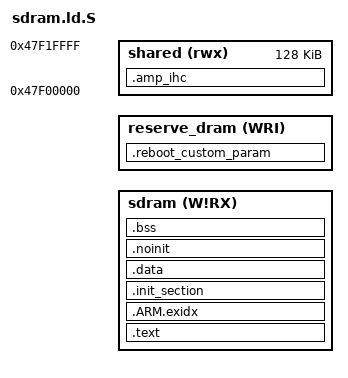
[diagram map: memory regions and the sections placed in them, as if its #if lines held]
/* Copyright (c) 2019-2025 Allwinner Technology Co., Ltd. ALL rights reserved.

 * Allwinner is a trademark of Allwinner Technology Co.,Ltd., registered in
 * the the People's Republic of China and other countries.
 * All Allwinner Technology Co.,Ltd. trademarks are used with permission.

 * DISCLAIMER
 * THIRD PARTY LICENCES MAY BE REQUIRED TO IMPLEMENT THE SOLUTION/PRODUCT.
 * IF YOU NEED TO INTEGRATE THIRD PARTY’S TECHNOLOGY (SONY, DTS, DOLBY, AVS OR MPEGLA, ETC.)
 * IN ALLWINNERS’SDK OR PRODUCTS, YOU SHALL BE SOLELY RESPONSIBLE TO OBTAIN
 * ALL APPROPRIATELY REQUIRED THIRD PARTY LICENCES.
 * ALLWINNER SHALL HAVE NO WARRANTY, INDEMNITY OR OTHER OBLIGATIONS WITH RESPECT TO MATTERS
 * COVERED UNDER ANY REQUIRED THIRD PARTY LICENSE.
 * YOU ARE SOLELY RESPONSIBLE FOR YOUR USAGE OF THIRD PARTY’S TECHNOLOGY.


 * THIS SOFTWARE IS PROVIDED BY ALLWINNER"AS IS" AND TO THE MAXIMUM EXTENT
 * PERMITTED BY LAW, ALLWINNER EXPRESSLY DISCLAIMS ALL WARRANTIES OF ANY KIND,
 * WHETHER EXPRESS, IMPLIED OR STATUTORY, INCLUDING WITHOUT LIMITATION REGARDING
 * THE TITLE, NON-INFRINGEMENT, ACCURACY, CONDITION, COMPLETENESS, PERFORMANCE
 * OR MERCHANTABILITY AND FITNESS FOR A PARTICULAR PURPOSE.
 * IN NO EVENT SHALL ALLWINNER BE LIABLE FOR ANY DIRECT, INDIRECT, INCIDENTAL,
 * SPECIAL, EXEMPLARY, OR CONSEQUENTIAL DAMAGES (INCLUDING, BUT
 * NOT LIMITED TO, PROCUREMENT OF SUBSTITUTE GOODS OR SERVICES;
 * LOSS OF USE, DATA, OR PROFITS, OR BUSINESS INTERRUPTION)
 * HOWEVER CAUSED AND ON ANY THEORY OF LIABILITY, WHETHER IN CONTRACT,
 * STRICT LIABILITY, OR TORT (INCLUDING NEGLIGENCE OR OTHERWISE)
 * ARISING IN ANY WAY OUT OF THE USE OF THIS SOFTWARE, EVEN IF ADVISED
 * OF THE POSSIBILITY OF SUCH DAMAGE.
 */

/* The pcDuino and 1GB of SDRAM beginning at virtual address 0x4000:0000.
 * Execution begins at address 0x4a00000, leaving 864MB for NuttX.
 */

MEMORY
{
    sdram (W!RX) : ORIGIN = CONFIG_RAM_START, LENGTH = CONFIG_RAM_SIZE
#ifdef CONFIG_RAMLOG_BUFSIZE
    reserve_dram (WRI) : ORIGIN = (0x48000000-CONFIG_RAMLOG_BUFSIZE), LENGTH = CONFIG_RAMLOG_BUFSIZE
#endif
#ifdef CONFIG_X4B_TEE
    shared (rwx) : ORIGIN = 0x47F00000, LENGTH = 128k
#endif
}

OUTPUT_FORMAT("elf32-littlearm", "elf32-littlearm", "elf32-littlearm")
OUTPUT_ARCH(arm)
ENTRY(entry)
ENTRY(_stext)
SECTIONS
{
    .text :
    {
        _stext = ABSOLUTE(.);
        __text_start = .;
        _head_start = ABSOLUTE(.);
        KEEP(*(.head))
        _head_end = ABSOLUTE(.);
        *(.vectors)
        *(.text .text.*)
        *(.fixup)
        *(.gnu.warning)
        *(.rodata .rodata.*)
        *(.gnu.linkonce.t.*)
        *(.glue_7)
        *(.glue_7t)
        *(.got)
        *(.gcc_except_table)
        *(.gnu.linkonce.r.*)
        *(.gnu.linkonce.armextab.*)
        *(.ARM.extab*)
        _etext = ABSOLUTE(.);
    } > sdram

    .ARM.exidx : ALIGN(4)
    {
        PROVIDE_HIDDEN (__exidx_start = .);
        *(.ARM.exidx* .gnu.linkonce.armexidx.*)
        PROVIDE_HIDDEN (__exidx_end = .);
    } > sdram

    .init_section :
    {
        _sinit = ABSOLUTE(.);
        KEEP(*(SORT_BY_INIT_PRIORITY(.init_array.*) SORT_BY_INIT_PRIORITY(.ctors.*)))
        KEEP(*(.init_array EXCLUDE_FILE(*crtbegin.o *crtbegin?.o *crtend.o *crtend?.o) .ctors))
        . = ALIGN(0x1000);
        _einit = ABSOLUTE(.);
    } > sdram

    .data :
    {
        _sdata = ABSOLUTE(.);
        *(.data .data.*)
        *(.gnu.linkonce.d.*)
        CONSTRUCTORS
        . = ALIGN(4);
        _edata = ABSOLUTE(.);
        KEEP(*(SORT(.miio_addon_list*)));
        KEEP(*(SORT(.scattered_array*)));
    } > sdram

#ifdef CONFIG_RAMLOG_BUFSIZE
	.reboot_custom_param (NOLOAD) :
	{
		KEEP(*(.reboot_custom_param*))
		. = ALIGN(4);
		__reboot_custom_param_end__ = .;
	} > reserve_dram
#endif
    /* Uninitialized data */

    .noinit :
    {
        _snoinit = ABSOLUTE(.);
        *(.noinit*)
        _enoinit = ABSOLUTE(.);
    } > sdram

    .bss :
    {
        _sbss = ABSOLUTE(.);
        *(.bss .bss.*)
        *(.gnu.linkonce.b.*)
        *(COMMON)
        . = ALIGN(4);
        _ebss = ABSOLUTE(.);
    } > sdram

    /* Stabs debugging sections. */

    .stab 0 : { *(.stab) }
    .stabstr 0 : { *(.stabstr) }
    .stab.excl 0 : { *(.stab.excl) }
    .stab.exclstr 0 : { *(.stab.exclstr) }
    .stab.index 0 : { *(.stab.index) }
    .stab.indexstr 0 : { *(.stab.indexstr) }
    .comment 0 : { *(.comment) }
    .debug_abbrev 0 : { *(.debug_abbrev) }
    .debug_info 0 : { *(.debug_info) }
    .debug_line 0 : { *(.debug_line) }
    .debug_pubnames 0 : { *(.debug_pubnames) }
    .debug_aranges 0 : { *(.debug_aranges) }

#ifdef CONFIG_X4B_TEE
      /* Shared memory for OpenAMP.  */
    .amp_ihc : ALIGN(0x1000)
    {
        __amp_ihc_load = LOADADDR(.amp_ihc);
        __amp_ihc_start = .;
        __amp_ihc_vma_start = .;
        *(.amp_ihc)
        . = ALIGN(0x1000);
        __amp_ihc_end = .;
        __amp_ihc_vma_end = .;
    } > shared
#endif
}
